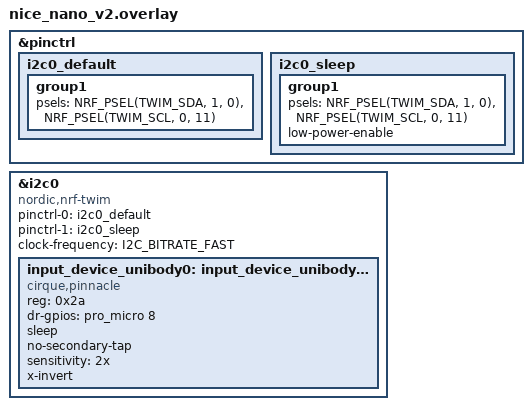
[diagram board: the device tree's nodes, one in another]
/**
 * Generated by Shield Wizard for ZMK
 * Applies to part "unibody" with controller "nice_nano_v2"
 */

// pin control for i2c0
// - SDA on D6
// - SCL on D7
&pinctrl {
    /* configuration for i2c0 device, default state */
    i2c0_default: i2c0_default {
        group1 {
            psels = <NRF_PSEL(TWIM_SDA, 1, 0)>,
                    <NRF_PSEL(TWIM_SCL, 0, 11)>;
        };
    };
    /* configuration for i2c0 device, sleep state */
    i2c0_sleep: i2c0_sleep {
        group1 {
            psels = <NRF_PSEL(TWIM_SDA, 1, 0)>,
                    <NRF_PSEL(TWIM_SCL, 0, 11)>;
            low-power-enable;
        };
    };
};
&i2c0 {
    compatible = "nordic,nrf-twim";
    status = "okay";
    pinctrl-0 = <&i2c0_default>;
    pinctrl-1 = <&i2c0_sleep>;
    pinctrl-names = "default", "sleep";
    clock-frequency = <I2C_BITRATE_FAST>;
};

// devices on i2c0

&i2c0 {
    input_device_unibody0: input_device_unibody0@2a {
        status = "okay";
        compatible = "cirque,pinnacle";
        reg = <0x2a>;
        dr-gpios = <&pro_micro 8 (GPIO_ACTIVE_HIGH | GPIO_PULL_DOWN)>;
        sleep;
        no-secondary-tap;
        sensitivity = "2x";

        // Enable the primary tap/click and invert the X axis.
        x-invert;
    };
};
